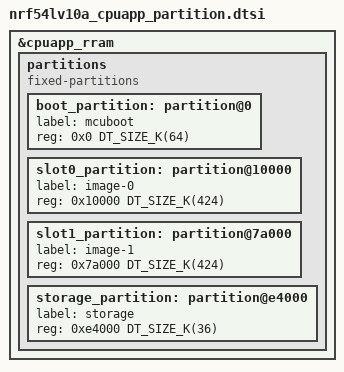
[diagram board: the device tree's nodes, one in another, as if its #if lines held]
/*
 * Copyright (c) 2026 Nordic Semiconductor ASA
 *
 * SPDX-License-Identifier: LicenseRef-Nordic-5-Clause
 */

&cpuapp_rram {
	partitions {
		compatible = "fixed-partitions";
		#address-cells = <1>;
		#size-cells = <1>;
		ranges;

		boot_partition: partition@0 {
			label = "mcuboot";
			reg = <0x0 DT_SIZE_K(64)>;
		};

#ifdef WITH_FLPR_PARTITIONS
		slot0_partition: partition@10000 {
			label = "image-0";
			reg = <0x10000 DT_SIZE_K(424)>;
		};

		slot1_partition: partition@7a000 {
			label = "image-1";
			reg = <0x7a000 DT_SIZE_K(424)>;
		};

		storage_partition: partition@e4000 {
			label = "storage";
			reg = <0xe4000 DT_SIZE_K(36)>;
		};
#else
		slot0_partition: partition@10000 {
			label = "image-0";
			reg = <0x10000 DT_SIZE_K(456)>;
		};

		slot1_partition: partition@82000 {
			label = "image-1";
			reg = <0x82000 DT_SIZE_K(456)>;
		};

		storage_partition: partition@f4000 {
			label = "storage";
			reg = <0xf4000 DT_SIZE_K(36)>;
		};
#endif
	};
};
